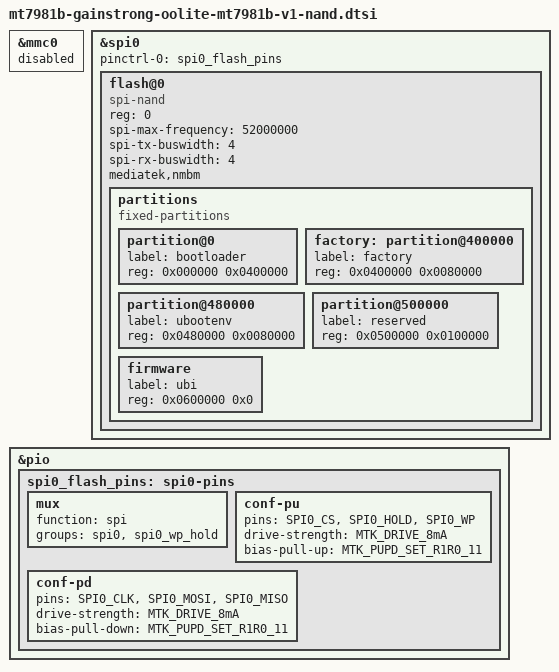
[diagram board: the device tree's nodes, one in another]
#include <dt-bindings/pinctrl/mt65xx.h>

&mmc0 {
	status = "disabled";
};

&spi0 {
	pinctrl-names = "default";
	pinctrl-0 = <&spi0_flash_pins>;
	#address-cells = <1>;
	#size-cells = <0>;
	status = "okay";

	flash@0 {
		compatible = "spi-nand";
		reg = <0>;
		spi-max-frequency = <52000000>;
		spi-tx-buswidth = <4>;
		spi-rx-buswidth = <4>;

		mediatek,nmbm;

		partitions {
			compatible = "fixed-partitions";
			#address-cells = <1>;
			#size-cells = <1>;

			/*
			 * Bootloader region (0x0 - 0x400000):
			 *   - BL2 @ 0x0
			 *   - FIP @ 0x40000
			 *
			 * Update this region using a combined bootloader image (BL2 + FIP)
			 * to keep the required offsets correct.
			 */
			partition@0 {
				label = "bootloader";
				reg = <0x000000 0x0400000>;
			};

			factory: partition@400000 {
				label = "factory";
				reg = <0x0400000 0x0080000>;
			};

			partition@480000 {
				label = "ubootenv";
				reg = <0x0480000 0x0080000>;
			};

			partition@500000 {
				label = "reserved";
				reg = <0x0500000 0x0100000>;
			};

			firmware {
				label = "ubi";
				reg = <0x0600000 0x0>;
			};
		};
	};
};
&pio {
	spi0_flash_pins: spi0-pins {
		mux {
			function = "spi";
			groups = "spi0", "spi0_wp_hold";
		};

		conf-pu {
			pins = "SPI0_CS", "SPI0_HOLD", "SPI0_WP";
			drive-strength = <MTK_DRIVE_8mA>;
			bias-pull-up = <MTK_PUPD_SET_R1R0_11>;
		};

		conf-pd {
			pins = "SPI0_CLK", "SPI0_MOSI", "SPI0_MISO";
			drive-strength = <MTK_DRIVE_8mA>;
			bias-pull-down = <MTK_PUPD_SET_R1R0_11>;
		};
	};
};
